# MM32G0001 register map
File version: 0.9.0
CPU: CM0 r0p0, little endian, no MPU, no FPU, 2 interrupt priority bits
Registers are 32-bit, read-write, reset 0x0 unless marked. A register's access mark holds for its fields unless they carry their own. Offsets are from the block's base; [hi:lo] are bit positions; {n}, {i} and the like mark numbered series.

## SPI1 — Serial peripheral interface
Base 0x40013000
0x00 TXREG
  [31:0] TXREG — Transmit data register
0x04 RXREG ro
  [31:0] RXREG — Receive data register
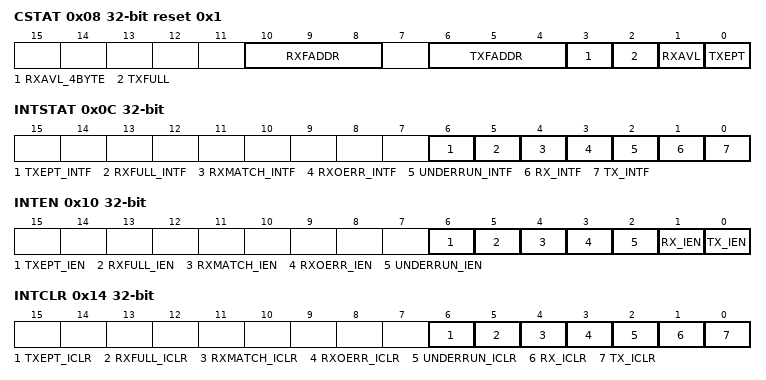
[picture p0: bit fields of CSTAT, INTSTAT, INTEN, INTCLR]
0x08 CSTAT ro reset 0x1
  [10:8] RXFADDR — Transmit FIFO address
  [6:4] TXFADDR — Receive FIFO address
  [3] RXAVL_4BYTE — Receive available 4 byte data message
  [2] TXFULL — Transmitter FIFO full status bit
  [1] RXAVL — Receive available byte data message
  [0] TXEPT — Transmitter empty bit
0x0C INTSTAT
  [6] TXEPT_INTF — Transmitter empty interrupt flag bit
  [5] RXFULL_INTF — RX FIFO full interrupt flag bit
  [4] RXMATCH_INTF — Receive data match the RXDNR number
  [3] RXOERR_INTF — Receive overrun error interrupt flag bit
  [2] UNDERRUN_INTF — SPI underrun interrupt flag bit
  [1] RX_INTF — Receive data available interrupt flag bit
  [0] TX_INTF — Transmit FIFO avialable interrupt flag bit
0x10 INTEN
  [6] TXEPT_IEN — Transmit empty interrupt enable bit
  [5] RXFULL_IEN — Receive FIFO full interrupt enable bit
  [4] RXMATCH_IEN — Receive data complete interrupt enable bit
  [3] RXOERR_IEN — Overrun error interrupt enable bit
  [2] UNDERRUN_IEN — Transmitter underrun interrupt enable bit(SPI slave mode only)
  [1] RX_IEN — Receive FIFO interrupt enable bit
  [0] TX_IEN — Transmit FIFO empty interrupt enable bit
0x14 INTCLR
  [6] TXEPT_ICLR — Transmitter empty interrupt clear bit
  [5] RXFULL_ICLR — Receiver buffer full interrupt clear bit
  [4] RXMATCH_ICLR — Receive completed interrupt clear bit
  [3] RXOERR_ICLR — Overrun error interrupt clear bit
  [2] UNDERRUN_ICLR — Transmitter underrun interrupt clear bit(SPI slave mode only)
  [1] RX_ICLR — Receive interrupt clear bit
  [0] TX_ICLR — Transmitter FIFO empty interrupt clear bit
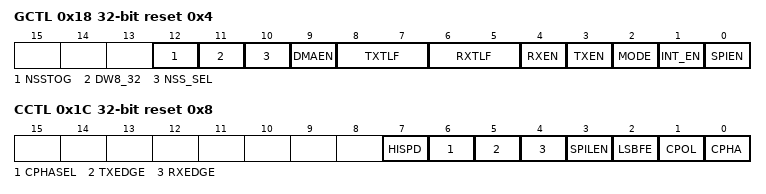
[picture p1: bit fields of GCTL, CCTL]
0x18 GCTL reset 0x4
  [12] NSSTOG — NSS selection signal is automatically flipped
  [11] DW8_32 — Valid byte or double-word data select signal
  [10] NSS_SEL — NSS select signal that from software and hardware
  [9] DMAEN — DMA access mode enable
  [8:7] TXTLF — TX FIFO trigger level bit
  [6:5] RXTLF — RX FIFO trigger level bit
  [4] RXEN — Receive enable bit
  [3] TXEN — Transmit enable bit
  [2] MODE — Master mode bit
  [1] INT_EN — SPI interrupt enable bit
  [0] SPIEN — SPI select bit
0x1C CCTL reset 0x8
  [7] HISPD — High speed slave mode
  [6] CPHASEL — CPHA polarity select
  [5] TXEDGE — Transmit data edge select
  [4] RXEDGE — Receive data edge select
  [3] SPILEN — SPI character length bit
  [2] LSBFE — LSI first enable bit
  [1] CPOL — Clock polarity select bit
  [0] CPHA — Clock phase select bit
0x20 SPBRG reset 0x2
  [15:0] SPBRG — SPI baud rate control register for baud rate
0x24 RXDNR reset 0x1
  [15:0] RXDNR — The register is used to hold a count of to be received bytes in next receive process
0x28 NSSR reset 0xFF
  [0] NSS — Chip select output signal in Master mode
0x2C EXTCTL reset 0x8
  [4:0] EXTLEN — Control SPI data length

## TIM3 — General purpose timer
Base 0x40000400
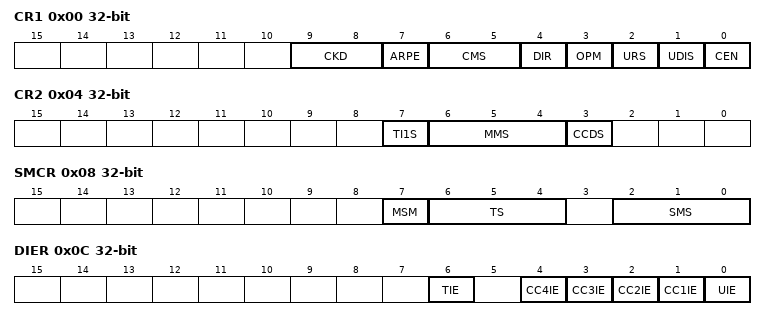
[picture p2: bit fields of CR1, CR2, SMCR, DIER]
0x00 CR1 — control register 1
  [9:8] CKD — Clock division
  [7] ARPE — Auto-reload preload enable
  [6:5] CMS — Center-aligned mode selection
  [4] DIR — Direction
  [3] OPM — One pulse mode
  [2] URS — Update request source
  [1] UDIS — Update disable
  [0] CEN — Counter enable
0x04 CR2 — control register 2
  [7] TI1S — TI1 selection
  [6:4] MMS — Master mode selection
  [3] CCDS — Compare DMA selection
0x08 SMCR — slave mode control register 1
  [7] MSM — Master/slave mode
  [6:4] TS — Trigger selection
  [2:0] SMS — Slave mode selection
0x0C DIER — DMA/Interrupt enable register
  [6] TIE — Trigger interrupt enable
  [n] CC{n}IE (n=1..4) — Compare {n} interrupt enable
  [0] UIE — Update interrupt enable
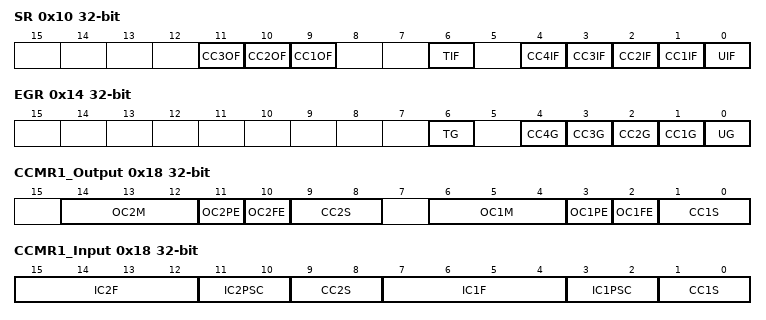
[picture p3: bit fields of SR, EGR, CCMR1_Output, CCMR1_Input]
0x10 SR — status register
  [11] CC3OF — Compare 3 overcapture flag
  [10] CC2OF — Compare 2 overcapture flag
  [9] CC1OF — Compare 1 overcapture flag
  [6] TIF — Trigger interrupt flag
  [n] CC{n}IF (n=1..4) — Compare {n} interrupt flag
  [0] UIF — Update interrupt flag
0x14 EGR wo — event generation register
  [6] TG — Trigger generation
  [n] CC{n}G (n=1..4) — compare {n} generation
  [0] UG — Update generation
0x18 CCMR1_Output — compare mode register 1 (output mode)
  [14:12] OC2M — Output compare 2 mode
  [11] OC2PE — Output compare 2 preload enable
  [10] OC2FE — Output compare 4 fast enable
  [9:8] CC2S — Capure/Compare 2 selection
  [6:4] OC1M — Output compare 1 mode
  [3] OC1PE — Output compare 1 preload enable
  [2] OC1FE — Output compare 1 fast enable
  [1:0] CC1S — Compare 2 output enable
0x18 CCMR1_Input (alternate view of CCMR1_Output) — compare mode register 1 (input mode)
  [15:12] IC2F — Input capture 2 filter
  [11:10] IC2PSC — Input capture 2 prescaler
  [9:8] CC2S — Compare 2 selection
  [7:4] IC1F — Input capture 1 filter
  [3:2] IC1PSC — Input capture 1 prescaler
  [1:0] CC1S — compare 1 selection
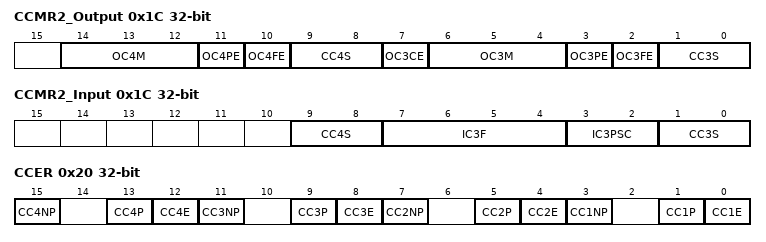
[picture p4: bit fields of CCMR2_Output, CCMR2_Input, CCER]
0x1C CCMR2_Output — compare mode register 2(output mode)
  [14:12] OC4M — Output compare 4 mode
  [11] OC4PE — Output compare 4 preload enable
  [10] OC4FE — Output compare 4 fast enable
  [9:8] CC4S — Compare 4 selection
  [7] OC3CE — Output compare 3 clear enable
  [6:4] OC3M — Output compare 3 mode
  [3] OC3PE — Output compare 3 preload enable
  [2] OC3FE — Output compare 3 fast enable
  [1:0] CC3S — Compare 3 selection
0x1C CCMR2_Input (alternate view of CCMR2_Output) — compare mode register 2 (input mode)
  [9:8] CC4S — Compare 4 selection
  [7:4] IC3F — Input capture 3 filter
  [3:2] IC3PSC — Input capture 3 prescaler
  [1:0] CC3S — compare 3 selection
0x20 CCER — compare enable register
  [4n-1] CC{n}NP (n=1..4) — Compare {n} complementary output polarity
  [4n-3] CC{n}P (n=1..4) — Compare {n} output polarity
  [4n-4] CC{n}E (n=1..4) — Compare {n} output enable
0x24 CNT — counter
  [15:0] CNT — Counter value
0x28 PSC — prescaler
  [15:0] PSC — Prescaler value
0x2C ARR — auto-reload register
  [15:0] ARR — Auto reload value
{0x30+4i} CCR{i} (i=1..4) — compare register {i}
  [15:0] CCR{i} — Compare {i} value
0x50 OR — option register
  [1:0] ETR_RMP — ETR remap

## TIM14 — Basic purpose timer
Base 0x40014000
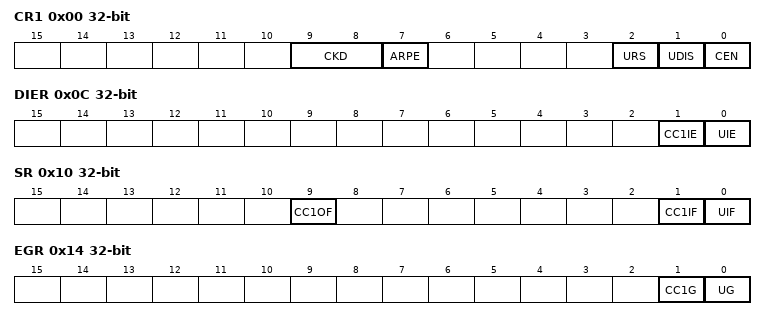
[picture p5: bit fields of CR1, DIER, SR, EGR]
0x00 CR1 — control register 1
  [9:8] CKD — Clock division
  [7] ARPE — Auto-reload preload enable
  [2] URS — Update request source
  [1] UDIS — Update disable
  [0] CEN — Counter enable
0x0C DIER — DMA/Interrupt enable register
  [1] CC1IE — Compare 1 interrupt enable
  [0] UIE — Update interrupt enable
0x10 SR — status register
  [9] CC1OF — Compare 1 overcapture flag
  [1] CC1IF — Compare 1 interrupt flag
  [0] UIF — Update interrupt flag
0x14 EGR wo — event generation register
  [1] CC1G — Compare 1 generation
  [0] UG — Update generation
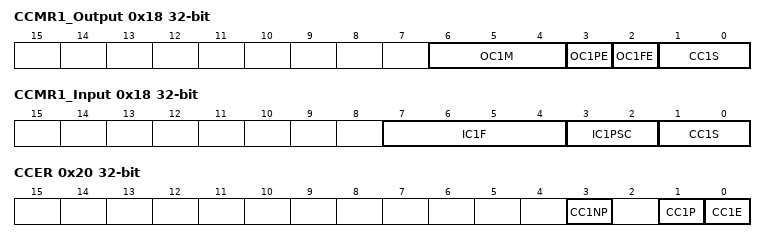
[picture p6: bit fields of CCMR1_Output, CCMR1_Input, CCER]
0x18 CCMR1_Output — compare mode register 1 (output mode)
  [6:4] OC1M — Output compare 1 mode
  [3] OC1PE — Output compare 1 preload enable
  [2] OC1FE — Output compare 1 fast enable
  [1:0] CC1S — Compare 2 output enable
0x18 CCMR1_Input (alternate view of CCMR1_Output) — compare mode register 1 (input mode)
  [7:4] IC1F — Input capture 1 filter
  [3:2] IC1PSC — Input capture 1 prescaler
  [1:0] CC1S — compare 1 selection
0x20 CCER — compare enable register
  [3] CC1NP — Compare 1 complementary output polarity
  [1] CC1P — Compare 1 output polarity
  [0] CC1E — Compare 1 output enable
0x24 CNT — counter
  [15:0] CNT — Counter value
0x28 PSC — prescaler
  [15:0] PSC — Prescaler value
0x2C ARR — auto-reload register
  [15:0] ARR — auto-reload value
0x30 RCR — repetition counter register
  [7:0] REP — Repetition counter value
0x34 CCR1 — compare register 1
  [15:0] CCR1 — Compare 1 value
0x44 BDTR — Break and dead time register
  [15] MOE — Main output enable

## USART1
Base 0x40013800
Same registers: USART2 0x40004400
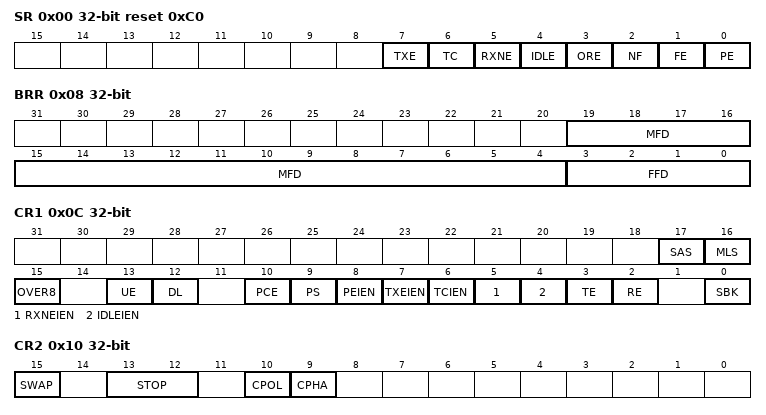
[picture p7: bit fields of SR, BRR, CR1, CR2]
0x00 SR reset 0xC0 — Status register
  [7] TXE ro, [6] TC ro, [5] RXNE write-0-clears, [4] IDLE ro, [3] ORE ro, [2] NF ro, [1] FE ro, [0] PE ro
0x04 DR reset 0x1FF — Data register
  [8:0] DR
0x08 BRR — Baud rate register
  [19:4] MFD, [3:0] FFD
0x0C CR1 — Control register 1
  [17] SAS, [16] MLS, [15] OVER8, [13] UE, [12] DL, [10] PCE, [9] PS, [8] PEIEN, [7] TXEIEN, [6] TCIEN, [5] RXNEIEN, [4] IDLEIEN, [3] TE, [2] RE, [0] SBK
0x10 CR2 — Control register 2
  [15] SWAP, [13:12] STOP, [10] CPOL, [9] CPHA
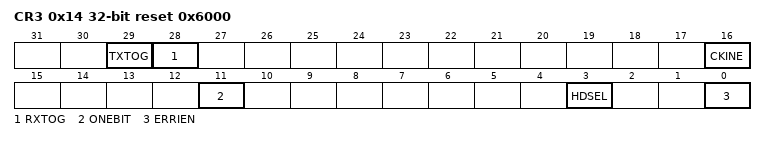
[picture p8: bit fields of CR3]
0x14 CR3 reset 0x6000 — Control register 3
  [29] TXTOG, [28] RXTOG, [16] CKINE, [11] ONEBIT, [3] HDSEL, [0] ERRIEN
